# ATxmega128D3 device description
Architecture: AVR8_XMEGA; Family: AVR XMEGA
Registers are 8-bit, access not given, no defined reset value unless marked. A register's access mark holds for its fields unless they carry their own. Offsets are from the block's base; [hi:lo] are bit positions; {n}, {i} and the like mark numbered series; 'fields as' and 'values as' point back to an identical list.

## DFLL
Instances: DFLLRC32M 0x0060, DFLLRC2M 0x0068
0x00 CTRL — Control Register
  [0] ENABLE — DFLL Enable
0x02 CALA — Calibration Register A
  [6:0] CALL — DFLL Calibration bits [6:0]
0x03 CALB — Calibration Register B
  [5:0] CALH — DFLL Calibration bits [12:7]
{0x4+i} COMP{i} (i=0..2) — Oscillator Compare Register {i}

## RST — Reset
Instances: RST 0x0078
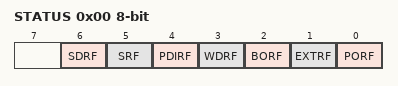
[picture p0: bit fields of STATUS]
0x00 STATUS
  [6] SDRF — Spike Detection Reset Flag
  [5] SRF — Software Reset Flag
  [4] PDIRF — Programming and Debug Interface Interface Reset Flag
  [3] WDRF — Watchdog Reset Flag
  [2] BORF — Brown-out Reset Flag
  [1] EXTRF — External Reset Flag
  [0] PORF — Power-on Reset Flag
0x01 CTRL — Control Register
  [0] SWRST — Software Reset

## WDT — Watch-Dog Timer
Instances: WDT 0x0080
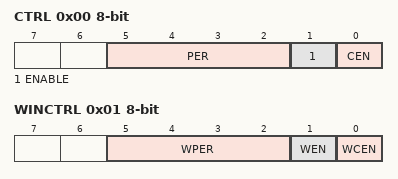
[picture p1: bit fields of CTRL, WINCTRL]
0x00 CTRL — Control
  [5:2] PER — Period
    0=8CLK (8 cycles (8ms @ 3.3V)); 1=16CLK (16 cycles (16ms @ 3.3V)); 2=32CLK (32 cycles (32ms @ 3.3V)); 3=64CLK (64 cycles (64ms @ 3.3V)); 4=128CLK (128 cycles (0.128s @ 3.3V)); 5=256CLK (256 cycles (0.256s @ 3.3V)); 6=512CLK (512 cycles (0.512s @ 3.3V)); 7=1KCLK (1K cycles (1s @ 3.3V)); 8=2KCLK (2K cycles (2s @ 3.3V)); 9=4KCLK (4K cycles (4s @ 3.3V)); 10=8KCLK (8K cycles (8s @ 3.3V))
  [1] ENABLE
  [0] CEN — Change Enable
0x01 WINCTRL — Windowed Mode Control
  [5:2] WPER — Windowed Mode Period
    values as CTRL.PER
  [1] WEN — Windowed Mode Enable
  [0] WCEN — Windowed Mode Change Enable
0x02 STATUS
  [0] SYNCBUSY — Syncronization busy

## MCU — MCU Control
Instances: MCU 0x0090
{0x0+i} DEVID{i} (i=0..2) — Device ID byte {i}
0x03 REVID — Revision ID
0x04 JTAGUID — JTAG User ID
0x06 MCUCR — MCU Control
  [0] JTAGD — JTAG Disable
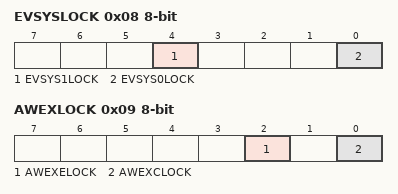
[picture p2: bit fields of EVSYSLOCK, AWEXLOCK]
0x08 EVSYSLOCK — Event System Lock
  [4] EVSYS1LOCK — Event Channel 4-7 Lock
  [0] EVSYS0LOCK — Event Channel 0-3 Lock
0x09 AWEXLOCK
  [2] AWEXELOCK — AWeX on T/C E0 Lock
  [0] AWEXCLOCK — AWeX on T/C C0 Lock

## PMIC — Programmable Multi-level Interrupt Controller
Instances: PMIC 0x00A0
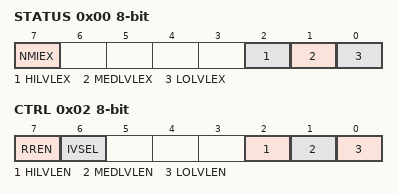
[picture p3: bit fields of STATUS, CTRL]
0x00 STATUS
  [7] NMIEX — Non-maskable Interrupt Executing
  [2] HILVLEX — High Level Interrupt Executing
  [1] MEDLVLEX — Medium Level Interrupt Executing
  [0] LOLVLEX — Low Level Interrupt Executing
0x01 INTPRI — Interrupt Priority
0x02 CTRL — Control Register
  [7] RREN — Round-Robin Priority Enable
  [6] IVSEL — Interrupt Vector Select
  [2] HILVLEN — High Level Enable
  [1] MEDLVLEN — Medium Level Enable
  [0] LOLVLEN — Low Level Enable

## CRC — Cyclic Redundancy Checker
Instances: CRC 0x0D0
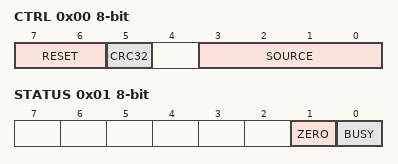
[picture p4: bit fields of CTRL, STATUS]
0x00 CTRL — Control Register
  [7:6] RESET
    0=NO (No Reset); 2=Reset CRC with CHECKSUM to all zeros; 3=Reset CRC with CHECKSUM to all ones
  [5] CRC32 — CRC Mode
  [3:0] SOURCE — Input Source
    0=DISABLE (Disabled); 1=IO (I/O Interface); 2=FLASH
0x01 STATUS
  [1] ZERO — Zero detection
  [0] BUSY
0x03 DATAIN — Data Input
{0x4+i} CHECKSUM{i} (i=0..3) — Checksum byte {i}

## EVSYS — Event System
Instances: EVSYS 0x0180
{0x0+i} CH{i}MUX (i=0..3) — Event Channel {i} Multiplexer
  [7:0] CHMUX
    0=OFF; 8=RTC_OVF (RTC Overflow); 9=RTC_CMP (RTC Compare Match); 16=ACA_CH0 (Analog Comparator A Channel 0); 17=ACA_CH1 (Analog Comparator A Channel 1); 18=ACA_WIN (Analog Comparator A Window); 32=ADCA_CH0 (ADC A Channel 0); {v}=PORTA_PIN{v-80} (v=80..87); {v}=PORTB_PIN{v-88} (v=88..95); {v}=PORTC_PIN{v-96} (v=96..103); {v}=PORTD_PIN{v-104} (v=104..111); {v}=PORTE_PIN{v-112} (v=112..119); {v}=PORTF_PIN{v-120} (v=120..127); 128=PRESCALER_1 (Prescaler, divide by 1); 129=PRESCALER_2 (Prescaler, divide by 2); 130=PRESCALER_4 (Prescaler, divide by 4); 131=PRESCALER_8 (Prescaler, divide by 8); 132=PRESCALER_16 (Prescaler, divide by 16); 133=PRESCALER_32 (Prescaler, divide by 32); 134=PRESCALER_64 (Prescaler, divide by 64); 135=PRESCALER_128 (Prescaler, divide by 128); 136=PRESCALER_256 (Prescaler, divide by 256); 137=PRESCALER_512 (Prescaler, divide by 512); 138=PRESCALER_1024 (Prescaler, divide by 1024); 139=PRESCALER_2048 (Prescaler, divide by 2048); 140=PRESCALER_4096 (Prescaler, divide by 4096); 141=PRESCALER_8192 (Prescaler, divide by 8192); 142=PRESCALER_16384 (Prescaler, divide by 16384); 143=PRESCALER_32768 (Prescaler, divide by 32768); 192=TCC0_OVF (Timer/Counter C0 Overflow); 193=TCC0_ERR (Timer/Counter C0 Error); 196=TCC0_CCA (Timer/Counter C0 Compare or Capture A); 197=TCC0_CCB (Timer/Counter C0 Compare or Capture B); 198=TCC0_CCC (Timer/Counter C0 Compare or Capture C); 199=TCC0_CCD (Timer/Counter C0 Compare or Capture D); 200=TCC1_OVF (Timer/Counter C1 Overflow); 201=TCC1_ERR (Timer/Counter C1 Error); 204=TCC1_CCA (Timer/Counter C1 Compare or Capture A); 205=TCC1_CCB (Timer/Counter C1 Compare or Capture B); 208=TCD0_OVF (Timer/Counter D0 Overflow); 209=TCD0_ERR (Timer/Counter D0 Error); 212=TCD0_CCA (Timer/Counter D0 Compare or Capture A); 213=TCD0_CCB (Timer/Counter D0 Compare or Capture B); 214=TCD0_CCC (Timer/Counter D0 Compare or Capture C); 215=TCD0_CCD (Timer/Counter D0 Compare or Capture D); 224=TCE0_OVF (Timer/Counter E0 Overflow); 225=TCE0_ERR (Timer/Counter E0 Error); 228=TCE0_CCA (Timer/Counter E0 Compare or Capture A); 229=TCE0_CCB (Timer/Counter E0 Compare or Capture B); 230=TCE0_CCC (Timer/Counter E0 Compare or Capture C); 231=TCE0_CCD (Timer/Counter E0 Compare or Capture D); 240=TCF0_OVF (Timer/Counter F0 Overflow); 241=TCF0_ERR (Timer/Counter F0 Error); 244=TCF0_CCA (Timer/Counter F0 Compare or Capture A); 245=TCF0_CCB (Timer/Counter F0 Compare or Capture B); 246=TCF0_CCC (Timer/Counter F0 Compare or Capture C); 247=TCF0_CCD (Timer/Counter F0 Compare or Capture D)
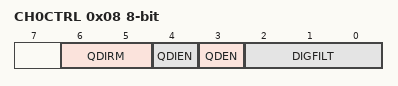
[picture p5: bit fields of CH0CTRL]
0x08 CH0CTRL — Channel 0 Control Register
  [6:5] QDIRM — Quadrature Decoder Index Recognition Mode
    0=QDPH0 = 0, QDPH90 = 0; 1=QDPH0 = 0, QDPH90 = 1; 2=QDPH0 = 1, QDPH90 = 0; 3=QDPH0 = 1, QDPH90 = 1
  [4] QDIEN — Quadrature Decoder Index Enable
  [3] QDEN — Quadrature Decoder Enable
  [2:0] DIGFILT — Digital Filter
    0=1SAMPLE; {v}={v+1}SAMPLES (v=1..7)
{0x8+i} CH{i}CTRL (i=1..3) — Channel {i} Control Register
  [2:0] DIGFILT — Digital Filter
    0=1SAMPLE; {v}={v+1}SAMPLES (v=1..7)
0x10 STROBE — Event Strobe
0x11 DATA — Event Data
